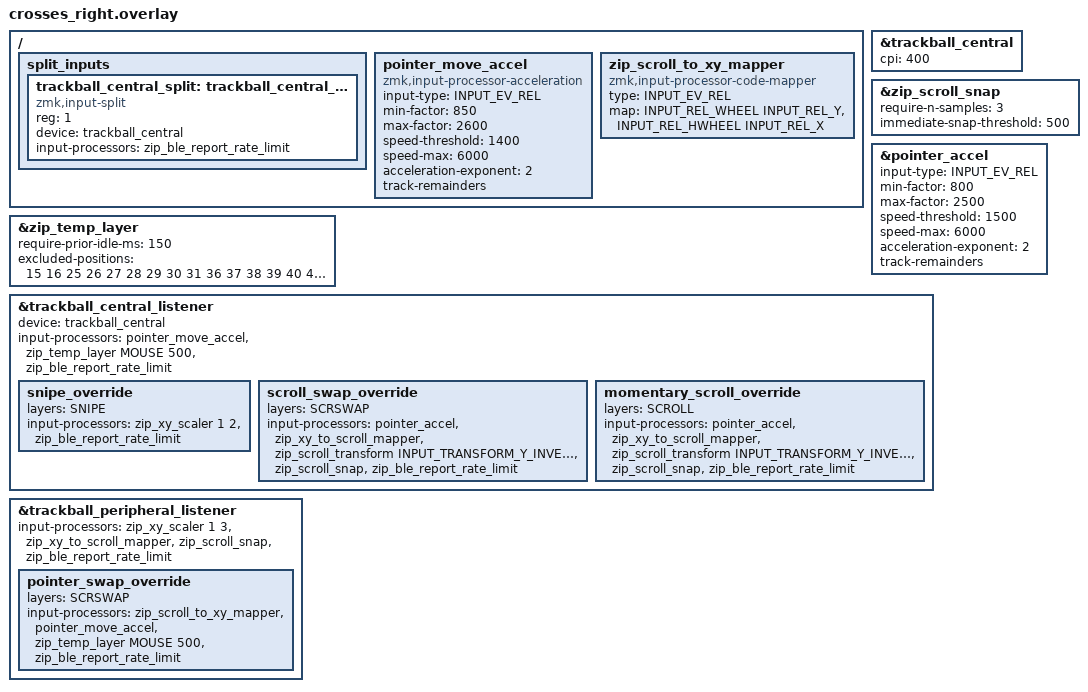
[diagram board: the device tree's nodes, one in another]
#include <scroll-snap.dtsi>
#include <behaviors/input_gestures_accel.dtsi>
#include <zephyr/dt-bindings/input/input-event-codes.h>
#include <dt-bindings/zmk/input_transform.h>

#define MOUSE   9
#define SNIPE   10
#define SCRSWAP 13
#define SCROLL  14

// Right (central) trackball: pointer at raw 400 cpi, halved to 200 cpi on the
// SNIPE layer for precision aiming. zip_temp_layer auto-activates the MOUSE
// layer for 500ms whenever the ball moves (with a 150ms prior-idle guard so
// casual typing motion doesn't trip it). zip_ble_report_rate_limit at the
// base of both listeners is the actual lag fix.

&zip_temp_layer {
    require-prior-idle-ms = <150>;
    // Keep MOUSE alive while using any real Mouse-layer binding; otherwise
    // ZMK drops to the previous layer before the key resolves.
    excluded-positions = <15 16 25 26 27 28 29 30 31 36 37 38 39 40 41 42 43 44 45 46 48 49 50 51 52 53>;
};

&trackball_central {
    cpi = <400>;
};

&zip_scroll_snap {
    require-n-samples = <3>;
    immediate-snap-threshold = <500>;
};

/ {
    split_inputs {
        trackball_central_split: trackball_central_split@1 {
            compatible = "zmk,input-split";
            reg = <1>;
        };
    };

    pointer_move_accel: pointer_move_accel {
        compatible = "zmk,input-processor-acceleration";
        status = "okay";
        #input-processor-cells = <0>;
        input-type = <INPUT_EV_REL>;
        min-factor = <850>;
        max-factor = <2600>;
        speed-threshold = <1400>;
        speed-max = <6000>;
        acceleration-exponent = <2>;
        track-remainders;
    };

    // Fallback for SCRSWAP: if the left half still sends pre-mapped scroll
    // wheel events, turn them back into pointer X/Y on the central half.
    zip_scroll_to_xy_mapper: zip_scroll_to_xy_mapper {
        compatible = "zmk,input-processor-code-mapper";
        #input-processor-cells = <0>;
        type = <INPUT_EV_REL>;
        map
            = <INPUT_REL_WHEEL INPUT_REL_Y>
            , <INPUT_REL_HWHEEL INPUT_REL_X>
            ;
    };
};

// Conservative pointer acceleration curve. Used on the left (peripheral)
// listener BEFORE the scroll mapper so a faster roll produces bigger
// scroll jumps. Tune by raising max-factor or lowering speed-max if you
// want bigger fast-scroll, or by raising min-factor (closer to 1000) if
// slow scrolls feel sluggish.
&pointer_accel {
    input-type = <INPUT_EV_REL>;
    min-factor = <800>;
    max-factor = <2500>;
    speed-threshold = <1500>;
    speed-max = <6000>;
    acceleration-exponent = <2>;
    track-remainders;
};

&trackball_central_listener {
    status = "okay";
    device = <&trackball_central>;
    input-processors
        = <&pointer_move_accel>
        , <&zip_temp_layer MOUSE 500>
        , <&zip_ble_report_rate_limit>
        ;

    snipe_override {
        layers = <SNIPE>;
        input-processors
            = <&zip_xy_scaler 1 2>
            , <&zip_ble_report_rate_limit>
            ;
    };

    // SCRSWAP toggle on Adjust flips ball roles: central becomes scroll, with
    // axis-locking + the same scroll-acceleration curve as the peripheral.
    scroll_swap_override {
        layers = <SCRSWAP>;
        input-processors
            = <&pointer_accel>
            , <&zip_xy_to_scroll_mapper>
            , <&zip_scroll_transform INPUT_TRANSFORM_Y_INVERT>
            , <&zip_scroll_snap>
            , <&zip_ble_report_rate_limit>
            ;
    };

    // Held momentary: hold the left inner thumb on the Mouse layer to make
    // the central ball scroll for as long as the key is held. Same accel.
    momentary_scroll_override {
        layers = <SCROLL>;
        input-processors
            = <&pointer_accel>
            , <&zip_xy_to_scroll_mapper>
            , <&zip_scroll_transform INPUT_TRANSFORM_Y_INVERT>
            , <&zip_scroll_snap>
            , <&zip_ble_report_rate_limit>
            ;
    };
};

&trackball_central_split {
    device = <&trackball_central>;
    input-processors = <&zip_ble_report_rate_limit>;
};

// Left (peripheral) trackball scrolls by default with axis-locking. SCRSWAP
// flips it to plain pointer. Scale before mapping so the scroll rate stays
// usable with the raw split trackball motion.
&trackball_peripheral_listener {
    status = "okay";
    input-processors
        = <&zip_xy_scaler 1 3>
        , <&zip_xy_to_scroll_mapper>
        , <&zip_scroll_snap>
        , <&zip_ble_report_rate_limit>
        ;

    pointer_swap_override {
        layers = <SCRSWAP>;
        input-processors
            = <&zip_scroll_to_xy_mapper>
            , <&pointer_move_accel>
            , <&zip_temp_layer MOUSE 500>
            , <&zip_ble_report_rate_limit>
            ;
    };
};
